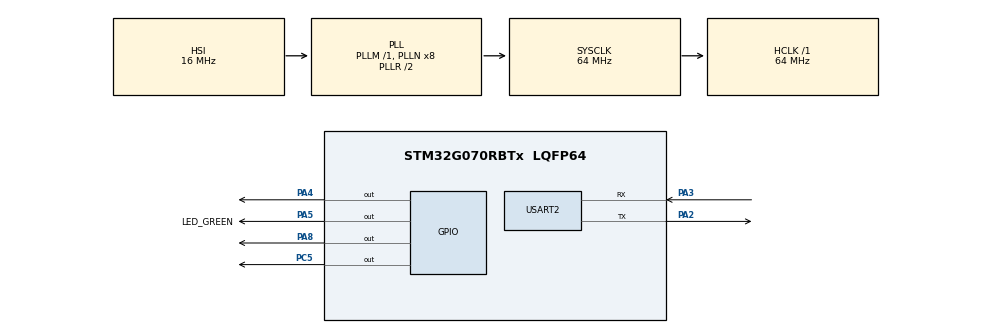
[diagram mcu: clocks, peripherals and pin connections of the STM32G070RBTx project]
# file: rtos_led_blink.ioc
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FREERTOS.Tasks01=Task1,8,128,StartTask1,Default,NULL,Dynamic,NULL,NULL;Task02,8,128,StartTask02,Default,NULL,Dynamic,NULL,NULL;Task03,8,128,StartTask03,Default,NULL,Dynamic,NULL,NULL
FREERTOS.configUSE_NEWLIB_REENTRANT=1
Mcu.Family=STM32G0
Mcu.Name=STM32G070RBTx
Mcu.Package=LQFP64
NVIC.TIM6_IRQn=true\:3\:0\:false\:false\:true\:false\:false\:true\:true
NVIC.TimeBase=TIM6_IRQn
NVIC.TimeBaseIP=TIM6
PA13.GPIO_Label=TMS
PA13.Mode=Serial_Wire
PA13.Signal=SYS_SWDIO
PA14-BOOT0.GPIO_Label=TCK
PA14-BOOT0.Mode=Serial_Wire
PA14-BOOT0.Signal=SYS_SWCLK
PA2.GPIO_PuPd=GPIO_PULLUP
PA2.Mode=Asynchronous
PA2.Signal=USART2_TX
PA3.GPIO_PuPd=GPIO_PULLUP
PA3.Mode=Asynchronous
PA3.Signal=USART2_RX
PA4.Signal=GPIO_Output
PA5.GPIO_Label=LED_GREEN
PA5.GPIO_Speed=GPIO_SPEED_FREQ_HIGH
PA5.Signal=GPIO_Output
PA8.Signal=GPIO_Output
PC13.Mode=SYS_WakeUp1
PC13.Signal=SYS_WKUP2
PC14-OSC32_IN\ (PC14).Mode=LSE-External-Oscillator
PC14-OSC32_IN\ (PC14).Signal=RCC_OSC32_IN
PC15-OSC32_OUT\ (PC15).Mode=LSE-External-Oscillator
PC15-OSC32_OUT\ (PC15).Signal=RCC_OSC32_OUT
PC5.Signal=GPIO_Output
PF0-OSC_IN\ (PF0).GPIO_Label=MCO
PF0-OSC_IN\ (PF0).Mode=HSE-External-Clock-Source
PF0-OSC_IN\ (PF0).Signal=RCC_OSC_IN
ProjectManager.HeapSize=0x200
ProjectManager.StackSize=0x400
ProjectManager.TargetToolchain=STM32CubeIDE
RCC.ADCFreq_Value=64000000
RCC.AHBFreq_Value=64000000
RCC.CortexFreq_Value=64000000
RCC.EXTERNAL_CLOCK_VALUE=12288000
RCC.HCLKFreq_Value=64000000
RCC.HSE_VALUE=8000000
RCC.HSI_VALUE=16000000
RCC.SYSCLKFreq_VALUE=64000000
RCC.SYSCLKSource=RCC_SYSCLKSOURCE_PLLCLK
RCC.VCOOutputFreq_Value=128000000
USART2.VirtualMode-Asynchronous=VM_ASYNC
USART2.WordLength=WORDLENGTH_8B
VP_FREERTOS_VS_CMSIS_V2.Mode=CMSIS_V2
VP_SYS_VS_DBSignals.Mode=DisableDeadBatterySignals
VP_SYS_VS_tim6.Mode=TIM6
board=NUCLEO-G070RB

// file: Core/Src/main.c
/* USER CODE BEGIN Header */
/**
  ******************************************************************************
  * @file           : main.c
  * @brief          : Main program body
  ******************************************************************************
  * @attention
  *
  * Copyright (c) 2024 STMicroelectronics.
  * All rights reserved.
  *
  * This software is licensed under terms that can be found in the LICENSE file
  * in the root directory of this software component.
  * If no LICENSE file comes with this software, it is provided AS-IS.
  *
  ******************************************************************************
  */
/* USER CODE END Header */
#include "main.h"
#include "cmsis_os.h"

UART_HandleTypeDef huart2;

/* Definitions for Task1 */
osThreadId_t Task1Handle;
const osThreadAttr_t Task1_attributes = {
  .name = "Task1",
  .priority = (osPriority_t) osPriorityLow,
  .stack_size = 128 * 4
};
/* Definitions for Task02 */
osThreadId_t Task02Handle;
const osThreadAttr_t Task02_attributes = {
  .name = "Task02",
  .priority = (osPriority_t) osPriorityLow,
  .stack_size = 128 * 4
};
/* Definitions for Task03 */
osThreadId_t Task03Handle;
const osThreadAttr_t Task03_attributes = {
  .name = "Task03",
  .priority = (osPriority_t) osPriorityLow,
  .stack_size = 128 * 4
};

void SystemClock_Config(void);
static void MX_GPIO_Init(void);
static void MX_USART2_UART_Init(void);
void StartTask1(void *argument);
void StartTask02(void *argument);
void StartTask03(void *argument);

int main(void)
{

  /* MCU Configuration--------------------------------------------------------*/

  /* Reset of all peripherals, Initializes the Flash interface and the Systick. */
  HAL_Init();

  /* Configure the system clock */
  SystemClock_Config();

  /* Initialize all configured peripherals */
  MX_GPIO_Init();
  MX_USART2_UART_Init();

  /* Init scheduler */
  osKernelInitialize();

  /* Create the thread(s) */
  /* creation of Task1 */
  Task1Handle = osThreadNew(StartTask1, NULL, &Task1_attributes);

  /* creation of Task02 */
  Task02Handle = osThreadNew(StartTask02, NULL, &Task02_attributes);

  /* creation of Task03 */
  Task03Handle = osThreadNew(StartTask03, NULL, &Task03_attributes);

  /* Start scheduler */
  osKernelStart();

  /* We should never get here as control is now taken by the scheduler */

  /* Infinite loop */
  while (1)
  {

  }
}

void SystemClock_Config(void)
{
  RCC_OscInitTypeDef RCC_OscInitStruct = {0};
  RCC_ClkInitTypeDef RCC_ClkInitStruct = {0};

  /** Configure the main internal regulator output voltage
  */
  HAL_PWREx_ControlVoltageScaling(PWR_REGULATOR_VOLTAGE_SCALE1);

  /** Initializes the RCC Oscillators according to the specified parameters
  * in the RCC_OscInitTypeDef structure.
  */
  RCC_OscInitStruct.OscillatorType = RCC_OSCILLATORTYPE_HSI;
  RCC_OscInitStruct.HSIState = RCC_HSI_ON;
  RCC_OscInitStruct.HSIDiv = RCC_HSI_DIV1;
  RCC_OscInitStruct.HSICalibrationValue = RCC_HSICALIBRATION_DEFAULT;
  RCC_OscInitStruct.PLL.PLLState = RCC_PLL_ON;
  RCC_OscInitStruct.PLL.PLLSource = RCC_PLLSOURCE_HSI;
  RCC_OscInitStruct.PLL.PLLM = RCC_PLLM_DIV1;
  RCC_OscInitStruct.PLL.PLLN = 8;
  RCC_OscInitStruct.PLL.PLLP = RCC_PLLP_DIV2;
  RCC_OscInitStruct.PLL.PLLR = RCC_PLLR_DIV2;
  if (HAL_RCC_OscConfig(&RCC_OscInitStruct) != HAL_OK)
  {
    Error_Handler();
  }

  /** Initializes the CPU, AHB and APB buses clocks
  */
  RCC_ClkInitStruct.ClockType = RCC_CLOCKTYPE_HCLK|RCC_CLOCKTYPE_SYSCLK
                              |RCC_CLOCKTYPE_PCLK1;
  RCC_ClkInitStruct.SYSCLKSource = RCC_SYSCLKSOURCE_PLLCLK;
  RCC_ClkInitStruct.AHBCLKDivider = RCC_SYSCLK_DIV1;
  RCC_ClkInitStruct.APB1CLKDivider = RCC_HCLK_DIV1;

  if (HAL_RCC_ClockConfig(&RCC_ClkInitStruct, FLASH_LATENCY_2) != HAL_OK)
  {
    Error_Handler();
  }
}

static void MX_USART2_UART_Init(void)
{

  huart2.Instance = USART2;
  huart2.Init.BaudRate = 115200;
  huart2.Init.WordLength = UART_WORDLENGTH_8B;
  huart2.Init.StopBits = UART_STOPBITS_1;
  huart2.Init.Parity = UART_PARITY_NONE;
  huart2.Init.Mode = UART_MODE_TX_RX;
  huart2.Init.HwFlowCtl = UART_HWCONTROL_NONE;
  huart2.Init.OverSampling = UART_OVERSAMPLING_16;
  huart2.Init.OneBitSampling = UART_ONE_BIT_SAMPLE_DISABLE;
  huart2.Init.ClockPrescaler = UART_PRESCALER_DIV1;
  huart2.AdvancedInit.AdvFeatureInit = UART_ADVFEATURE_NO_INIT;
  if (HAL_UART_Init(&huart2) != HAL_OK)
  {
    Error_Handler();
  }
  if (HAL_UARTEx_SetTxFifoThreshold(&huart2, UART_TXFIFO_THRESHOLD_1_8) != HAL_OK)
  {
    Error_Handler();
  }
  if (HAL_UARTEx_SetRxFifoThreshold(&huart2, UART_RXFIFO_THRESHOLD_1_8) != HAL_OK)
  {
    Error_Handler();
  }
  if (HAL_UARTEx_DisableFifoMode(&huart2) != HAL_OK)
  {
    Error_Handler();
  }

}

static void MX_GPIO_Init(void)
{
  GPIO_InitTypeDef GPIO_InitStruct = {0};

  /* GPIO Ports Clock Enable */
  __HAL_RCC_GPIOC_CLK_ENABLE();
  __HAL_RCC_GPIOF_CLK_ENABLE();
  __HAL_RCC_GPIOA_CLK_ENABLE();

  /*Configure GPIO pin Output Level */
  HAL_GPIO_WritePin(GPIOA, GPIO_PIN_4|LED_GREEN_Pin|GPIO_PIN_8, GPIO_PIN_RESET);

  /*Configure GPIO pin Output Level */
  HAL_GPIO_WritePin(GPIOC, GPIO_PIN_5, GPIO_PIN_RESET);

  /*Configure GPIO pins : PA4 PA8 */
  GPIO_InitStruct.Pin = GPIO_PIN_4|GPIO_PIN_8;
  GPIO_InitStruct.Mode = GPIO_MODE_OUTPUT_PP;
  GPIO_InitStruct.Pull = GPIO_NOPULL;
  GPIO_InitStruct.Speed = GPIO_SPEED_FREQ_LOW;
  HAL_GPIO_Init(GPIOA, &GPIO_InitStruct);

  /*Configure GPIO pin : LED_GREEN_Pin */
  GPIO_InitStruct.Pin = LED_GREEN_Pin;
  GPIO_InitStruct.Mode = GPIO_MODE_OUTPUT_PP;
  GPIO_InitStruct.Pull = GPIO_NOPULL;
  GPIO_InitStruct.Speed = GPIO_SPEED_FREQ_HIGH;
  HAL_GPIO_Init(LED_GREEN_GPIO_Port, &GPIO_InitStruct);

  /*Configure GPIO pin : PC5 */
  GPIO_InitStruct.Pin = GPIO_PIN_5;
  GPIO_InitStruct.Mode = GPIO_MODE_OUTPUT_PP;
  GPIO_InitStruct.Pull = GPIO_NOPULL;
  GPIO_InitStruct.Speed = GPIO_SPEED_FREQ_LOW;
  HAL_GPIO_Init(GPIOC, &GPIO_InitStruct);

}

void StartTask1(void *argument)
{
  /* USER CODE BEGIN 5 */
  /* Infinite loop */
  for(;;)
  {
	uint8_t task1_mes[20] = "Task one running \r\n";
	HAL_UART_Transmit(&huart2,task1_mes,sizeof(task1_mes),10);
	HAL_GPIO_TogglePin(GPIOC, GPIO_PIN_5);
    osDelay(1000);
  }
  /* USER CODE END 5 */
}

void StartTask02(void *argument)
{
  /* USER CODE BEGIN StartTask02 */
  /* Infinite loop */
  for(;;)
  {
	uint8_t task2_mes[20] = "Task two running \r\n";
	HAL_UART_Transmit(&huart2,task2_mes,sizeof(task2_mes),10);
	HAL_GPIO_TogglePin(GPIOA, GPIO_PIN_8);
    osDelay(2000);
  }
  /* USER CODE END StartTask02 */
}

void StartTask03(void *argument)
{
  /* USER CODE BEGIN StartTask03 */
  /* Infinite loop */
  for(;;)
  {
	uint8_t task3_mes[] = "Task three running \r\n";
	HAL_UART_Transmit(&huart2,task3_mes,sizeof(task3_mes),10);
	HAL_GPIO_TogglePin(GPIOA, GPIO_PIN_4);
    osDelay(3000);
  }
  /* USER CODE END StartTask03 */
}

void HAL_TIM_PeriodElapsedCallback(TIM_HandleTypeDef *htim)
{
  if (htim->Instance == TIM6) {
    HAL_IncTick();
  }
}

void Error_Handler(void)
{
  __disable_irq();
  while (1)
  {
  }
}
